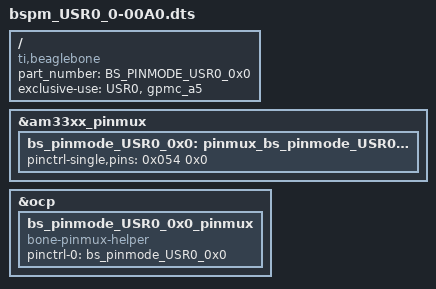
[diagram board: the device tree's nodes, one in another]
/*
 * This is a (mostly) template-generated file from BoneScript modified from Kilobaser.com's Device-Tree Overlay Generator, which turns off the USR0 LED
 */


/dts-v1/;
/plugin/;

/{
    compatible = "ti,beaglebone", "ti,beaglebone-black";
    part_number = "BS_PINMODE_USR0_0x0";

    exclusive-use =
        "USR0",
        "gpmc_a5";

    fragment@0 {
        target = <&am33xx_pinmux>;
        __overlay__ {
            bs_pinmode_USR0_0x0: pinmux_bs_pinmode_USR0_0x0 {
                pinctrl-single,pins = <0x054 0x0>;
            };
        };
    };

    fragment@1 {
        target = <&ocp>;
        __overlay__ {
            bs_pinmode_USR0_0x0_pinmux {
                compatible = "bone-pinmux-helper";
                status = "okay";
                pinctrl-names = "default";
                pinctrl-0 = <&bs_pinmode_USR0_0x0>;
            };
        };
    };
};
